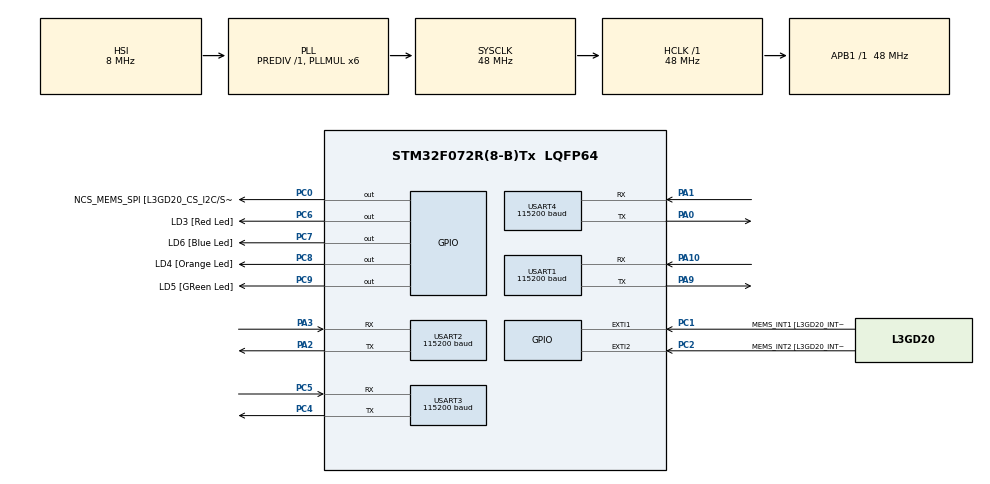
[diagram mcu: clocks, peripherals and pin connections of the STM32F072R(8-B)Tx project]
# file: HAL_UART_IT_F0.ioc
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Mcu.Family=STM32F0
Mcu.Name=STM32F072R(8-B)Tx
Mcu.Package=LQFP64
NVIC.USART1_IRQn=true\:1\:0\:true\:false\:true
NVIC.USART2_IRQn=true\:1\:0\:true\:false\:true
NVIC.USART3_4_IRQn=true\:1\:0\:true\:false\:true
PA0.Mode=Asynchronous
PA0.Signal=USART4_TX
PA1.Mode=Asynchronous
PA1.Signal=USART4_RX
PA10.Mode=Asynchronous
PA10.Signal=USART1_RX
PA11.GPIO_Label=USBF4_DM
PA11.Signal=USB_DM
PA12.GPIO_Label=USBF4_DP
PA12.Signal=USB_DP
PA13.GPIO_Label=SWDIO
PA13.Mode=Serial_Wire
PA13.Signal=SYS_SWDIO
PA14.GPIO_Label=SWCLK
PA14.Mode=Serial_Wire
PA14.Signal=SYS_SWCLK
PA2.Mode=Asynchronous
PA2.Signal=USART2_TX
PA3.Mode=Asynchronous
PA3.Signal=USART2_RX
PA9.Mode=Asynchronous
PA9.Signal=USART1_TX
PB10.GPIO_Label=I2C2_SCL[EXT/RF-E2P_SCL]
PB10.Signal=I2C2_SCL
PB11.GPIO_Label=I2C2_SDA[EXT/RF-E2P_SDA]
PB11.Signal=I2C2_SDA
PB13.GPIO_Label=SPI2_SCK [L3GD20_SCL/SPC]
PB13.Signal=SPI2_SCK
PB14.GPIO_Label=SPI2_MISO [L3GD20_SDO]
PB14.Signal=SPI2_MISO
PB15.GPIO_Label=SPI2_MOSI [L3GD20_SDA/SDI]
PB15.Signal=SPI2_MOSI
PC0.GPIO_Label=NCS_MEMS_SPI [L3GD20_CS_I2C/SPI]
PC0.Signal=GPIO_Output
PC1.GPIO_Label=MEMS_INT1 [L3GD20_INT1]
PC1.GPIO_ModeDefaultEXTI=GPIO_MODE_EVT_RISING
PC1.Signal=GPXTI1
PC2.GPIO_Label=MEMS_INT2 [L3GD20_INT2]
PC2.GPIO_ModeDefaultEXTI=GPIO_MODE_EVT_RISING
PC2.Signal=GPXTI2
PC4.Mode=Asynchronous
PC4.Signal=USART3_TX
PC5.Mode=Asynchronous
PC5.Signal=USART3_RX
PC6.GPIO_Label=LD3 [Red Led]
PC6.Signal=GPIO_Output
PC7.GPIO_Label=LD6 [Blue Led]
PC7.Signal=GPIO_Output
PC8.GPIO_Label=LD4 [Orange Led]
PC8.Signal=GPIO_Output
PC9.GPIO_Label=LD5 [GReen Led]
PC9.Signal=GPIO_Output
ProjectManager.HeapSize=0x200
ProjectManager.StackSize=0x400
ProjectManager.TargetToolchain=SW4STM32
RCC.AHBFreq_Value=48000000
RCC.APB1Freq_Value=48000000
RCC.APB1TimFreq_Value=48000000
RCC.HCLKFreq_Value=48000000
RCC.PLLMUL=RCC_PLL_MUL6
RCC.SYSCLKFreq_VALUE=48000000
RCC.SYSCLKSource=RCC_SYSCLKSOURCE_PLLCLK
USART1.BaudRate=115200
USART1.WordLength=UART_WORDLENGTH_8B
USART2.BaudRate=115200
USART2.WordLength=UART_WORDLENGTH_8B
USART3.BaudRate=115200
USART3.WordLength=UART_WORDLENGTH_8B
USART4.BaudRate=115200
USART4.WordLength=UART_WORDLENGTH_8B
board=STM32F072B-DISCO

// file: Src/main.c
/**
  ******************************************************************************
  * File Name          : main.c
  * Description        : Main program body
  ******************************************************************************
  *
  * COPYRIGHT(c) 2016 STMicroelectronics
  *
  * Redistribution and use in source and binary forms, with or without modification,
  * are permitted provided that the following conditions are met:
  *   1. Redistributions of source code must retain the above copyright notice,
  *      this list of conditions and the following disclaimer.
  *   2. Redistributions in binary form must reproduce the above copyright notice,
  *      this list of conditions and the following disclaimer in the documentation
  *      and/or other materials provided with the distribution.
  *   3. Neither the name of STMicroelectronics nor the names of its contributors
  *      may be used to endorse or promote products derived from this software
  *      without specific prior written permission.
  *
  * THIS SOFTWARE IS PROVIDED BY THE COPYRIGHT HOLDERS AND CONTRIBUTORS "AS IS"
  * AND ANY EXPRESS OR IMPLIED WARRANTIES, INCLUDING, BUT NOT LIMITED TO, THE
  * IMPLIED WARRANTIES OF MERCHANTABILITY AND FITNESS FOR A PARTICULAR PURPOSE ARE
  * DISCLAIMED. IN NO EVENT SHALL THE COPYRIGHT HOLDER OR CONTRIBUTORS BE LIABLE
  * FOR ANY DIRECT, INDIRECT, INCIDENTAL, SPECIAL, EXEMPLARY, OR CONSEQUENTIAL
  * DAMAGES (INCLUDING, BUT NOT LIMITED TO, PROCUREMENT OF SUBSTITUTE GOODS OR
  * SERVICES; LOSS OF USE, DATA, OR PROFITS; OR BUSINESS INTERRUPTION) HOWEVER
  * CAUSED AND ON ANY THEORY OF LIABILITY, WHETHER IN CONTRACT, STRICT LIABILITY,
  * OR TORT (INCLUDING NEGLIGENCE OR OTHERWISE) ARISING IN ANY WAY OUT OF THE USE
  * OF THIS SOFTWARE, EVEN IF ADVISED OF THE POSSIBILITY OF SUCH DAMAGE.
  *
  ******************************************************************************
  */
#include "stm32f0xx_hal.h"

UART_HandleTypeDef huart1;
UART_HandleTypeDef huart2;
UART_HandleTypeDef huart3;
UART_HandleTypeDef huart4;

/* USER CODE BEGIN PV */
/* Private variables ---------------------------------------------------------*/

/* USER CODE END PV */

void SystemClock_Config(void);
void Error_Handler(void);
static void MX_GPIO_Init(void);
static void MX_USART4_UART_Init(void);
static void MX_USART1_UART_Init(void);
static void MX_USART2_UART_Init(void);
static void MX_USART3_UART_Init(void);

/* USER CODE BEGIN PFP */
/* Private function prototypes -----------------------------------------------*/

/* USER CODE END PFP */

int main(void)
{

  /* MCU Configuration----------------------------------------------------------*/

  /* Reset of all peripherals, Initializes the Flash interface and the Systick. */
  HAL_Init();

  /* Configure the system clock */
  SystemClock_Config();

  /* Initialize all configured peripherals */
  MX_GPIO_Init();
  MX_USART4_UART_Init();
  MX_USART1_UART_Init();
  MX_USART2_UART_Init();
  MX_USART3_UART_Init();

  /* USER CODE BEGIN 2 */
  UARTInit();
  /* USER CODE END 2 */

  /* Infinite loop */
  while (1)
  {

  /* USER CODE BEGIN 3 */
	  UARTLoopDemo();
  }
  /* USER CODE END 3 */

}

/** System Clock Configuration
*/
void SystemClock_Config(void)
{

  RCC_OscInitTypeDef RCC_OscInitStruct;
  RCC_ClkInitTypeDef RCC_ClkInitStruct;
  RCC_PeriphCLKInitTypeDef PeriphClkInit;

  RCC_OscInitStruct.OscillatorType = RCC_OSCILLATORTYPE_HSI;
  RCC_OscInitStruct.HSIState = RCC_HSI_ON;
  RCC_OscInitStruct.HSICalibrationValue = 16;
  RCC_OscInitStruct.PLL.PLLState = RCC_PLL_ON;
  RCC_OscInitStruct.PLL.PLLSource = RCC_PLLSOURCE_HSI;
  RCC_OscInitStruct.PLL.PLLMUL = RCC_PLL_MUL6;
  RCC_OscInitStruct.PLL.PREDIV = RCC_PREDIV_DIV1;
  if (HAL_RCC_OscConfig(&RCC_OscInitStruct) != HAL_OK)
  {
    Error_Handler();
  }

  RCC_ClkInitStruct.ClockType = RCC_CLOCKTYPE_HCLK|RCC_CLOCKTYPE_SYSCLK
                              |RCC_CLOCKTYPE_PCLK1;
  RCC_ClkInitStruct.SYSCLKSource = RCC_SYSCLKSOURCE_PLLCLK;
  RCC_ClkInitStruct.AHBCLKDivider = RCC_SYSCLK_DIV1;
  RCC_ClkInitStruct.APB1CLKDivider = RCC_HCLK_DIV1;
  if (HAL_RCC_ClockConfig(&RCC_ClkInitStruct, FLASH_LATENCY_1) != HAL_OK)
  {
    Error_Handler();
  }

  PeriphClkInit.PeriphClockSelection = RCC_PERIPHCLK_USART1|RCC_PERIPHCLK_USART2;
  PeriphClkInit.Usart1ClockSelection = RCC_USART1CLKSOURCE_PCLK1;
  PeriphClkInit.Usart2ClockSelection = RCC_USART2CLKSOURCE_PCLK1;
  if (HAL_RCCEx_PeriphCLKConfig(&PeriphClkInit) != HAL_OK)
  {
    Error_Handler();
  }

  HAL_SYSTICK_Config(HAL_RCC_GetHCLKFreq()/1000);

  HAL_SYSTICK_CLKSourceConfig(SYSTICK_CLKSOURCE_HCLK);

  /* SysTick_IRQn interrupt configuration */
  HAL_NVIC_SetPriority(SysTick_IRQn, 0, 0);
}

/* USART1 init function */
static void MX_USART1_UART_Init(void)
{

  huart1.Instance = USART1;
  huart1.Init.BaudRate = 115200;
  huart1.Init.WordLength = UART_WORDLENGTH_8B;
  huart1.Init.StopBits = UART_STOPBITS_1;
  huart1.Init.Parity = UART_PARITY_NONE;
  huart1.Init.Mode = UART_MODE_TX_RX;
  huart1.Init.HwFlowCtl = UART_HWCONTROL_NONE;
  huart1.Init.OverSampling = UART_OVERSAMPLING_16;
  huart1.Init.OneBitSampling = UART_ONE_BIT_SAMPLE_DISABLE;
  huart1.AdvancedInit.AdvFeatureInit = UART_ADVFEATURE_NO_INIT;
  if (HAL_UART_Init(&huart1) != HAL_OK)
  {
    Error_Handler();
  }

}

/* USART2 init function */
static void MX_USART2_UART_Init(void)
{

  huart2.Instance = USART2;
  huart2.Init.BaudRate = 115200;
  huart2.Init.WordLength = UART_WORDLENGTH_8B;
  huart2.Init.StopBits = UART_STOPBITS_1;
  huart2.Init.Parity = UART_PARITY_NONE;
  huart2.Init.Mode = UART_MODE_TX_RX;
  huart2.Init.HwFlowCtl = UART_HWCONTROL_NONE;
  huart2.Init.OverSampling = UART_OVERSAMPLING_16;
  huart2.Init.OneBitSampling = UART_ONE_BIT_SAMPLE_DISABLE;
  huart2.AdvancedInit.AdvFeatureInit = UART_ADVFEATURE_NO_INIT;
  if (HAL_UART_Init(&huart2) != HAL_OK)
  {
    Error_Handler();
  }

}

/* USART3 init function */
static void MX_USART3_UART_Init(void)
{

  huart3.Instance = USART3;
  huart3.Init.BaudRate = 115200;
  huart3.Init.WordLength = UART_WORDLENGTH_8B;
  huart3.Init.StopBits = UART_STOPBITS_1;
  huart3.Init.Parity = UART_PARITY_NONE;
  huart3.Init.Mode = UART_MODE_TX_RX;
  huart3.Init.HwFlowCtl = UART_HWCONTROL_NONE;
  huart3.Init.OverSampling = UART_OVERSAMPLING_16;
  huart3.Init.OneBitSampling = UART_ONE_BIT_SAMPLE_DISABLE;
  huart3.AdvancedInit.AdvFeatureInit = UART_ADVFEATURE_NO_INIT;
  if (HAL_UART_Init(&huart3) != HAL_OK)
  {
    Error_Handler();
  }

}

/* USART4 init function */
static void MX_USART4_UART_Init(void)
{

  huart4.Instance = USART4;
  huart4.Init.BaudRate = 115200;
  huart4.Init.WordLength = UART_WORDLENGTH_8B;
  huart4.Init.StopBits = UART_STOPBITS_1;
  huart4.Init.Parity = UART_PARITY_NONE;
  huart4.Init.Mode = UART_MODE_TX_RX;
  huart4.Init.HwFlowCtl = UART_HWCONTROL_NONE;
  huart4.Init.OverSampling = UART_OVERSAMPLING_16;
  huart4.Init.OneBitSampling = UART_ONE_BIT_SAMPLE_DISABLE;
  huart4.AdvancedInit.AdvFeatureInit = UART_ADVFEATURE_NO_INIT;
  if (HAL_UART_Init(&huart4) != HAL_OK)
  {
    Error_Handler();
  }

}

/** Configure pins as
        * Analog
        * Input
        * Output
        * EVENT_OUT
        * EXTI
     PB10   ------> I2C2_SCL
     PB11   ------> I2C2_SDA
     PB13   ------> SPI2_SCK
     PB14   ------> SPI2_MISO
     PB15   ------> SPI2_MOSI
*/
static void MX_GPIO_Init(void)
{

  GPIO_InitTypeDef GPIO_InitStruct;

  /* GPIO Ports Clock Enable */
  __HAL_RCC_GPIOC_CLK_ENABLE();
  __HAL_RCC_GPIOA_CLK_ENABLE();
  __HAL_RCC_GPIOB_CLK_ENABLE();

  /*Configure GPIO pin Output Level */
  HAL_GPIO_WritePin(GPIOC, NCS_MEMS_SPI_Pin|LD3_Pin|LD6_Pin|LD4_Pin
                          |LD5_Pin, GPIO_PIN_RESET);

  /*Configure GPIO pins : NCS_MEMS_SPI_Pin LD3_Pin LD6_Pin LD4_Pin
                           LD5_Pin */
  GPIO_InitStruct.Pin = NCS_MEMS_SPI_Pin|LD3_Pin|LD6_Pin|LD4_Pin
                          |LD5_Pin;
  GPIO_InitStruct.Mode = GPIO_MODE_OUTPUT_PP;
  GPIO_InitStruct.Pull = GPIO_NOPULL;
  GPIO_InitStruct.Speed = GPIO_SPEED_FREQ_LOW;
  HAL_GPIO_Init(GPIOC, &GPIO_InitStruct);

  /*Configure GPIO pins : MEMS_INT1_Pin MEMS_INT2_Pin */
  GPIO_InitStruct.Pin = MEMS_INT1_Pin|MEMS_INT2_Pin;
  GPIO_InitStruct.Mode = GPIO_MODE_EVT_RISING;
  GPIO_InitStruct.Pull = GPIO_NOPULL;
  HAL_GPIO_Init(GPIOC, &GPIO_InitStruct);

  /*Configure GPIO pins : PB10 PB11 */
  GPIO_InitStruct.Pin = GPIO_PIN_10|GPIO_PIN_11;
  GPIO_InitStruct.Mode = GPIO_MODE_AF_OD;
  GPIO_InitStruct.Pull = GPIO_PULLUP;
  GPIO_InitStruct.Speed = GPIO_SPEED_FREQ_HIGH;
  GPIO_InitStruct.Alternate = GPIO_AF1_I2C2;
  HAL_GPIO_Init(GPIOB, &GPIO_InitStruct);

  /*Configure GPIO pins : PB13 PB14 PB15 */
  GPIO_InitStruct.Pin = GPIO_PIN_13|GPIO_PIN_14|GPIO_PIN_15;
  GPIO_InitStruct.Mode = GPIO_MODE_AF_PP;
  GPIO_InitStruct.Pull = GPIO_NOPULL;
  GPIO_InitStruct.Speed = GPIO_SPEED_FREQ_HIGH;
  GPIO_InitStruct.Alternate = GPIO_AF0_SPI2;
  HAL_GPIO_Init(GPIOB, &GPIO_InitStruct);

}

void Error_Handler(void)
{
  while(1)
  {
  }
}

/************************ (C) COPYRIGHT STMicroelectronics *****END OF FILE****/
